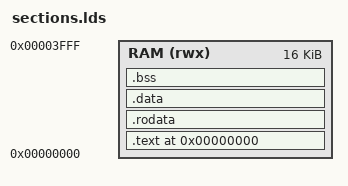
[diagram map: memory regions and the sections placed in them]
OUTPUT_ARCH(riscv)
ENTRY(_start)

MEMORY { RAM (rwx) : ORIGIN = 0x00000000, LENGTH = 16K }

SECTIONS {
    . = 0x0;
    .text : { *(.text.init) *(.text*) } > RAM
    .rodata : { *(.rodata*) *(.srodata*) } > RAM
    .data : { *(.data*) *(.sdata*) } > RAM
    .bss : {
        _bss_start = .;
        *(.bss*) *(.sbss*) *(COMMON)
        _bss_end = .;
    } > RAM
    _stack_top = ORIGIN(RAM) + LENGTH(RAM);
}
